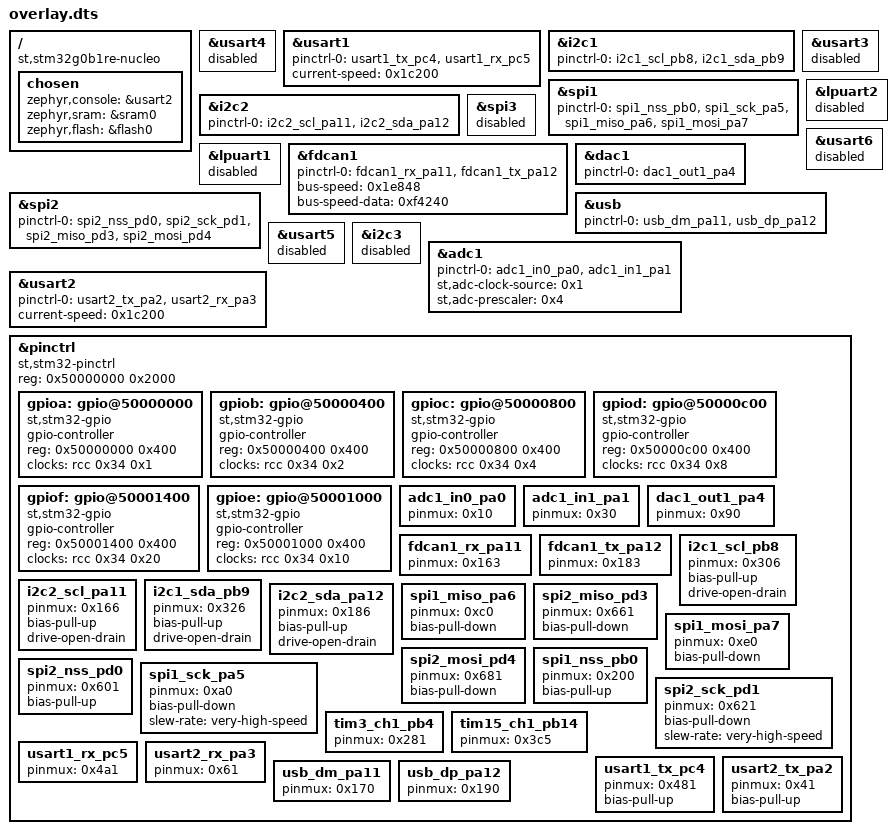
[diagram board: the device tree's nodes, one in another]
/ {
	compatible = "st,stm32g0b1re-nucleo";
	chosen {
		zephyr,console = &usart2;
		zephyr,sram = &sram0;
		zephyr,flash = &flash0;
	};
};
&usart4{
	status = "disabled";
};
&usart1{
	status = "okay";
	pinctrl-0 = < &usart1_tx_pc4 &usart1_rx_pc5 >;
	pinctrl-names = "default";
	current-speed = < 0x1c200 >;
};
&i2c1{
	status = "okay";
	pinctrl-0 = < &i2c1_scl_pb8 &i2c1_sda_pb9 >;
	pinctrl-names = "default";
};
&usart3{
	status = "disabled";
};
&spi1{
	status = "okay";
	pinctrl-0 = < &spi1_nss_pb0 &spi1_sck_pa5 &spi1_miso_pa6 &spi1_mosi_pa7 >;
	pinctrl-names = "default";
};
&i2c2{
	status = "okay";
	pinctrl-0 = < &i2c2_scl_pa11 &i2c2_sda_pa12 >;
	pinctrl-names = "default";
};
&lpuart2{
	status = "disabled";
};
&usart6{
	status = "disabled";
};
&spi3{
	status = "disabled";
};
&lpuart1{
	status = "disabled";
};
&fdcan1{
	status = "okay";
	pinctrl-0 = < &fdcan1_rx_pa11 &fdcan1_tx_pa12 >;
	pinctrl-names = "default";
	bus-speed = < 0x1e848 >;
	bus-speed-data = < 0xf4240 >;
};
&dac1{
	status = "okay";
	pinctrl-0 = < &dac1_out1_pa4 >;
	pinctrl-names = "default";
};
&spi2{
	status = "okay";
	pinctrl-0 = < &spi2_nss_pd0 &spi2_sck_pd1 &spi2_miso_pd3 &spi2_mosi_pd4 >;
	pinctrl-names = "default";
};
&usb{
	status = "okay";
	pinctrl-0 = < &usb_dm_pa11 &usb_dp_pa12 >;
	pinctrl-names = "default";
};
&usart5{
	status = "disabled";
};
&i2c3{
	status = "disabled";
};
&adc1{
	status = "okay";
	pinctrl-0 = < &adc1_in0_pa0 &adc1_in1_pa1 >;
	pinctrl-names = "default";
	st,adc-clock-source = < 0x1 >;
	st,adc-prescaler = < 0x4 >;
};
&usart2{
	status = "okay";
	pinctrl-0 = < &usart2_tx_pa2 &usart2_rx_pa3 >;
	pinctrl-names = "default";
	current-speed = < 0x1c200 >;
};
&pinctrl{
	compatible = "st,stm32-pinctrl";
	#address-cells = < 0x1 >;
	#size-cells = < 0x1 >;
	reg = < 0x50000000 0x2000 >;
	gpioa: gpio@50000000 {
		compatible = "st,stm32-gpio";
		gpio-controller;
		#gpio-cells = < 0x2 >;
		reg = < 0x50000000 0x400 >;
		clocks = < &rcc 0x34 0x1 >;
	};
	gpiob: gpio@50000400 {
		compatible = "st,stm32-gpio";
		gpio-controller;
		#gpio-cells = < 0x2 >;
		reg = < 0x50000400 0x400 >;
		clocks = < &rcc 0x34 0x2 >;
	};
	gpioc: gpio@50000800 {
		compatible = "st,stm32-gpio";
		gpio-controller;
		#gpio-cells = < 0x2 >;
		reg = < 0x50000800 0x400 >;
		clocks = < &rcc 0x34 0x4 >;
	};
	gpiod: gpio@50000c00 {
		compatible = "st,stm32-gpio";
		gpio-controller;
		#gpio-cells = < 0x2 >;
		reg = < 0x50000c00 0x400 >;
		clocks = < &rcc 0x34 0x8 >;
	};
	gpiof: gpio@50001400 {
		compatible = "st,stm32-gpio";
		gpio-controller;
		#gpio-cells = < 0x2 >;
		reg = < 0x50001400 0x400 >;
		clocks = < &rcc 0x34 0x20 >;
	};
	gpioe: gpio@50001000 {
		compatible = "st,stm32-gpio";
		gpio-controller;
		#gpio-cells = < 0x2 >;
		reg = < 0x50001000 0x400 >;
		clocks = < &rcc 0x34 0x10 >;
	};
	adc1_in0_pa0: adc1_in0_pa0 {
		pinmux = < 0x10 >;
	};
	adc1_in1_pa1: adc1_in1_pa1 {
		pinmux = < 0x30 >;
	};
	dac1_out1_pa4: dac1_out1_pa4 {
		pinmux = < 0x90 >;
	};
	fdcan1_rx_pa11: fdcan1_rx_pa11 {
		pinmux = < 0x163 >;
	};
	fdcan1_tx_pa12: fdcan1_tx_pa12 {
		pinmux = < 0x183 >;
	};
	i2c1_scl_pb8: i2c1_scl_pb8 {
		pinmux = < 0x306 >;
		bias-pull-up;
		drive-open-drain;
	};
	i2c2_scl_pa11: i2c2_scl_pa11 {
		pinmux = < 0x166 >;
		bias-pull-up;
		drive-open-drain;
	};
	i2c1_sda_pb9: i2c1_sda_pb9 {
		pinmux = < 0x326 >;
		bias-pull-up;
		drive-open-drain;
	};
	i2c2_sda_pa12: i2c2_sda_pa12 {
		pinmux = < 0x186 >;
		bias-pull-up;
		drive-open-drain;
	};
	spi1_miso_pa6: spi1_miso_pa6 {
		pinmux = < 0xc0 >;
		bias-pull-down;
	};
	spi2_miso_pd3: spi2_miso_pd3 {
		pinmux = < 0x661 >;
		bias-pull-down;
	};
	spi1_mosi_pa7: spi1_mosi_pa7 {
		pinmux = < 0xe0 >;
		bias-pull-down;
	};
	spi2_mosi_pd4: spi2_mosi_pd4 {
		pinmux = < 0x681 >;
		bias-pull-down;
	};
	spi1_nss_pb0: spi1_nss_pb0 {
		pinmux = < 0x200 >;
		bias-pull-up;
	};
	spi2_nss_pd0: spi2_nss_pd0 {
		pinmux = < 0x601 >;
		bias-pull-up;
	};
	spi1_sck_pa5: spi1_sck_pa5 {
		pinmux = < 0xa0 >;
		bias-pull-down;
		slew-rate = "very-high-speed";
	};
	spi2_sck_pd1: spi2_sck_pd1 {
		pinmux = < 0x621 >;
		bias-pull-down;
		slew-rate = "very-high-speed";
	};
	tim3_ch1_pb4: tim3_ch1_pb4 {
		pinmux = < 0x281 >;
	};
	tim15_ch1_pb14: tim15_ch1_pb14 {
		pinmux = < 0x3c5 >;
	};
	usart1_rx_pc5: usart1_rx_pc5 {
		pinmux = < 0x4a1 >;
	};
	usart2_rx_pa3: usart2_rx_pa3 {
		pinmux = < 0x61 >;
	};
	usart1_tx_pc4: usart1_tx_pc4 {
		pinmux = < 0x481 >;
		bias-pull-up;
	};
	usart2_tx_pa2: usart2_tx_pa2 {
		pinmux = < 0x41 >;
		bias-pull-up;
	};
	usb_dm_pa11: usb_dm_pa11 {
		pinmux = < 0x170 >;
	};
	usb_dp_pa12: usb_dp_pa12 {
		pinmux = < 0x190 >;
	};
};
